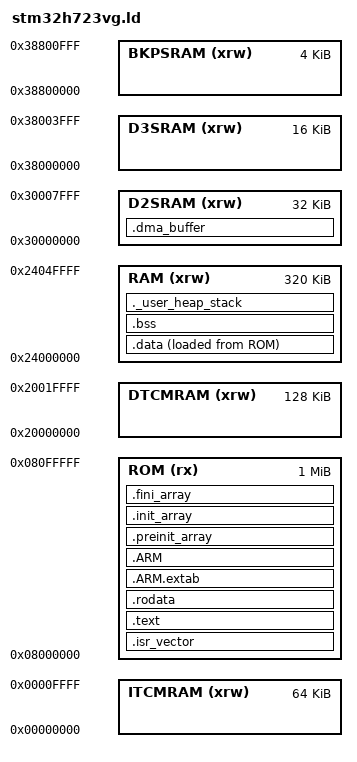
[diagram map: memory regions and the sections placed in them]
ENTRY(Reset_Handler)

_estack = ORIGIN(RAM) + LENGTH(RAM);
_Min_Heap_Size = 0x400;
_Min_Stack_Size = 0x800;

MEMORY
{
  ITCMRAM   (xrw) : ORIGIN = 0x00000000, LENGTH = 64K
  DTCMRAM   (xrw) : ORIGIN = 0x20000000, LENGTH = 128K
  RAM       (xrw) : ORIGIN = 0x24000000, LENGTH = 320K
  D2SRAM    (xrw) : ORIGIN = 0x30000000, LENGTH = 32K
  D3SRAM    (xrw) : ORIGIN = 0x38000000, LENGTH = 16K
  BKPSRAM   (xrw) : ORIGIN = 0x38800000, LENGTH = 4K
  ROM       (rx)  : ORIGIN = 0x08000000, LENGTH = 1024K
}

SECTIONS
{
  .isr_vector :
  {
    . = ALIGN(4);
    KEEP(*(.isr_vector))
    . = ALIGN(4);
  } >ROM

  .text :
  {
    . = ALIGN(4);
    *(.text)
    *(.text*)
    *(.glue_7)
    *(.glue_7t)
    *(.eh_frame)
    KEEP (*(.init))
    KEEP (*(.fini))
    . = ALIGN(4);
    _etext = .;
  } >ROM

  .rodata :
  {
    . = ALIGN(4);
    *(.rodata)
    *(.rodata*)
    . = ALIGN(4);
  } >ROM

  .ARM.extab :
  {
    . = ALIGN(4);
    *(.ARM.extab* .gnu.linkonce.armextab.*)
    . = ALIGN(4);
  } >ROM

  .ARM :
  {
    . = ALIGN(4);
    __exidx_start = .;
    *(.ARM.exidx*)
    __exidx_end = .;
    . = ALIGN(4);
  } >ROM

  .preinit_array :
  {
    . = ALIGN(4);
    PROVIDE_HIDDEN (__preinit_array_start = .);
    KEEP (*(.preinit_array*))
    PROVIDE_HIDDEN (__preinit_array_end = .);
    . = ALIGN(4);
  } >ROM

  .init_array :
  {
    . = ALIGN(4);
    PROVIDE_HIDDEN (__init_array_start = .);
    KEEP (*(SORT(.init_array.*)))
    KEEP (*(.init_array*))
    PROVIDE_HIDDEN (__init_array_end = .);
    . = ALIGN(4);
  } >ROM

  .fini_array :
  {
    . = ALIGN(4);
    PROVIDE_HIDDEN (__fini_array_start = .);
    KEEP (*(SORT(.fini_array.*)))
    KEEP (*(.fini_array*))
    PROVIDE_HIDDEN (__fini_array_end = .);
    . = ALIGN(4);
  } >ROM

  _sidata = LOADADDR(.data);

  .data :
  {
    . = ALIGN(4);
    _sdata = .;
    *(.data)
    *(.data*)
    *(.RamFunc)
    *(.RamFunc*)
    . = ALIGN(4);
    _edata = .;
  } >RAM AT> ROM

  .dma_buffer (NOLOAD) :
  {
    . = ALIGN(32);
    *(.dma_buffer)
    *(.dma_buffer*)
    . = ALIGN(32);
  } >D2SRAM

  .bss :
  {
    . = ALIGN(4);
    _sbss = .;
    __bss_start__ = _sbss;
    *(.bss)
    *(.bss*)
    *(COMMON)
    . = ALIGN(4);
    _ebss = .;
    __bss_end__ = _ebss;
  } >RAM

  ._user_heap_stack :
  {
    . = ALIGN(8);
    PROVIDE ( end = . );
    PROVIDE ( _end = . );
    . = . + _Min_Heap_Size;
    . = . + _Min_Stack_Size;
    . = ALIGN(8);
  } >RAM

  /DISCARD/ :
  {
    libc.a ( * )
    libm.a ( * )
    libgcc.a ( * )
  }

  .ARM.attributes 0 : { *(.ARM.attributes) }
}
